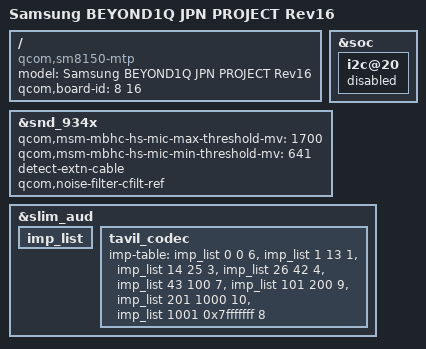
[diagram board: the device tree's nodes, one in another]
/* Copyright (c) 2016-2017, The Linux Foundation. All rights reserved.
 *
 * This program is free software; you can redistribute it and/or modify
 * it under the terms of the GNU General Public License version 2 and
 * only version 2 as published by the Free Software Foundation.
 *
 * This program is distributed in the hope that it will be useful,
 * but WITHOUT ANY WARRANTY; without even the implied warranty of
 * MERCHANTABILITY or FITNESS FOR A PARTICULAR PURPOSE.  See the
 * GNU General Public License for more details.
 */

/dts-v1/;
/plugin/;

#include <dt-bindings/clock/qcom,gcc-sm8150.h>
#include <dt-bindings/clock/qcom,camcc-sm8150.h>
#include <dt-bindings/clock/qcom,rpmh.h>
#include <dt-bindings/interrupt-controller/arm-gic.h>

#include "../qcom/sm8150-mtp.dtsi"
#include "sm8150-sec-common.dtsi"
#include "sm8150-sec-beyondqlte-pm-common.dtsi"
#include "sm8150-sec-beyondqlte-pm-jpn-common.dtsi"
#include "sm8150-sec-beyond1qlte-input-common.dtsi"
#include "sm8150-sec-beyond1qlte-r16.dtsi"
#include "sm8150-sec-beyond1qlte-pinctrl-r16.dtsi"
#include "sm8150-sec-beyond1qlte-display-r00.dtsi"
#include "sm8150-sec-beyond2qlte-displayport-r14.dtsi"
#include "battery-data-beyond1qlte-common.dtsi"
#include "sm8150-max77705.dtsi"
#include "sm8150-max77705-motor.dtsi"
#include "sm8150-sec-beyond2qlte-sensor-common.dtsi"
#include "sm8150-sec-beyond1qlte-fingerprint-sensor-r11.dtsi"
#include "sm8150-sec-beyond2qlte-jpn-felica-r08.dtsi"
#include "sm8150-sec-beyond2qlte-jpn-isdbt-r13.dtsi"
#include "sm8150-camera-sensor-beyond1qlte-r08.dtsi"
#include "sm8150-sec-beyondq-mst-r04.dtsi"

/ {
	model = "Samsung BEYOND1Q JPN PROJECT Rev16";
	compatible = "qcom,sm8150-mtp", "qcom,sm8150", "qcom,mtp";
	qcom,board-id = <8 16>;
};

&soc{
	i2c@20{
		status = "disabled";
	};
};

&snd_934x {
	qcom,msm-mbhc-hs-mic-max-threshold-mv = <1700>;
	qcom,msm-mbhc-hs-mic-min-threshold-mv = <641>;
	detect-extn-cable;
	qcom,noise-filter-cfilt-ref;
};

&slim_aud {
	imp_list: imp_list {
		#list-imp-cells = <3>;
	};

	tavil_codec {
		imp-table = <&imp_list 0 0 6>,
				 <&imp_list 1 13 1>,
				 <&imp_list 14 25 3>,
				 <&imp_list 26 42 4>,
				 <&imp_list 43 100 7>,
				 <&imp_list 101 200 9>,
				 <&imp_list 201 1000 10>,
				 <&imp_list 1001 0x7fffffff 8>;
	};
};

